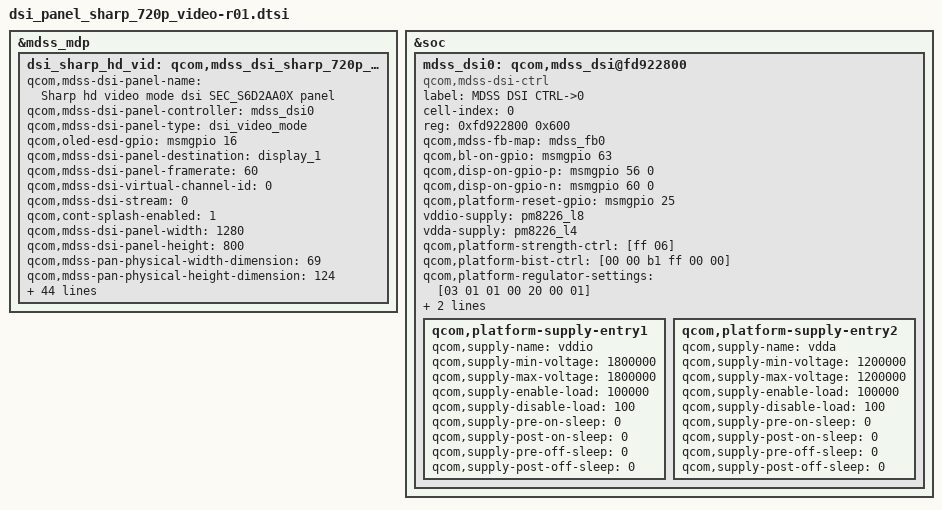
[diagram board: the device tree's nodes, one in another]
/* Copyright (c) 2013, The Linux Foundation. All rights reserved.
 *
 * This program is free software; you can redistribute it and/or modify
 * it under the terms of the GNU General Public License version 2 and
 * only version 2 as published by the Free Software Foundation.
 *
 * This program is distributed in the hope that it will be useful,
 * but WITHOUT ANY WARRANTY; without even the implied warranty of
 * MERCHANTABILITY or FITNESS FOR A PARTICULAR PURPOSE.  See the
 * GNU General Public License for more details.
 */
&mdss_mdp {
		dsi_sharp_hd_vid: qcom,mdss_dsi_sharp_720p_video {
		qcom,mdss-dsi-panel-name = "Sharp hd video mode dsi SEC_S6D2AA0X panel";
		qcom,mdss-dsi-panel-controller = <&mdss_dsi0>;
		qcom,mdss-dsi-panel-type = "dsi_video_mode";
		qcom,oled-esd-gpio = <&msmgpio 16 0>;
		qcom,mdss-dsi-panel-destination = "display_1";
		qcom,mdss-dsi-panel-framerate = <60>;
		qcom,mdss-dsi-virtual-channel-id = <0>;
		qcom,mdss-dsi-stream = <0>;
		qcom,cont-splash-enabled = <1>;
		qcom,mdss-dsi-panel-width = <1280>;
		qcom,mdss-dsi-panel-height = <800>;
		qcom,mdss-pan-physical-width-dimension = <69>; /* <Width> real size of panel in mm */
		qcom,mdss-pan-physical-height-dimension = <124>; /*<Height> real size of panel in mm */
		qcom,mdss-dsi-h-front-porch = <192>;
		qcom,mdss-dsi-h-back-porch = <30>;
		qcom,mdss-dsi-h-front-porch-jdi = <134>;	// Adding for JDI
		qcom,mdss-dsi-h-back-porch-jdi = <65>;		// Adding for JDI
		qcom,mdss-dsi-h-pulse-width = <4>;
		qcom,mdss-dsi-h-sync-skew = <0>;
		qcom,mdss-dsi-v-back-porch = <6>;
		qcom,mdss-dsi-v-front-porch = <8>;
		qcom,mdss-dsi-v-pulse-width = <2>;
		qcom,mdss-dsi-h-left-border = <0>;
		qcom,mdss-dsi-h-right-border = <0>;
		qcom,mdss-dsi-v-top-border = <0>;
		qcom,mdss-dsi-v-bottom-border = <0>;
		qcom,mdss-dsi-bpp = <24>;
		qcom,mdss-dsi-color-order = <0>;
		qcom,mdss-dsi-underflow-color = <0xff>;
		qcom,mdss-dsi-border-color = <0>;
		qcom,mdss-dsi-mdp-trigger = <0x0>;
		qcom,mdss-dsi-dma-trigger = <0x04>;
		qcom,mdss-dsi-bl-min-level = <10>;
		qcom,mdss-dsi-bl-max-level = <120>;
		qcom,mdss-dsi-bl-pmic-control-type = "bl_ctrl_dcs";
		qcom,mdss-pan-dsi-t-clk-pre = <0x1b>;
		qcom,mdss-pan-dsi-t-clk-post = <0x04>;
        qcom,mdss-dsi-panel-timings = [30 1C 12 00 42 44 18 20 16 03 04 00];
		qcom,mdss-dsi-lane-0-state;
		qcom,mdss-dsi-lane-1-state;
		qcom,mdss-dsi-lane-2-state;
		qcom,mdss-dsi-lane-3-state;
		qcom,mdss-dsi-bllp-eof-power-mode;
		qcom,mdss-dsi-bllp-power-mode;
		qcom,mdss-dsi-traffic-mode = <2>;
		qcom,mdss-force-clk-lane-hs = <1>;
		qcom,mdss-dsi-lane-map = <0>;
		qcom,mdss-dsi-h-sync-pulse = <0>;
		qcom,mdss-dsi-panel-clock-rate = <462000000>;


		qcom,mdss-dsi-on-command = [
/*TC358764/65XBG DSI Basic Parameters*/
			29 01 00 00 00 00 06 3C 01 06 00 05 00
			29 01 00 00 00 00 06 14 01 04 00 00 00
			29 01 00 00 00 00 06 64 01 04 00 00 00
			29 01 00 00 00 00 06 68 01 04 00 00 00
			29 01 00 00 00 00 06 6C 01 04 00 00 00
			29 01 00 00 00 00 06 70 01 04 00 00 00
			29 01 00 00 00 00 06 34 01 1F 00 00 00
			29 01 00 00 00 00 06 10 02 1F 00 00 00
			29 01 00 00 00 00 06 04 01 01 00 00 00
			29 01 00 00 00 00 06 04 02 01 00 00 00

/*TC358764/65XBG Timing and mode setting*/
			29 01 00 00 00 00 06 50 04 20 01 F0 03
			29 01 00 00 00 00 06 54 04 02 00 30 00
			29 01 00 00 00 00 06 58 04 20 03 30 00
			29 01 00 00 00 00 06 5C 04 02 00 40 00
			29 01 00 00 00 00 06 60 04 00 05 20 00

			29 01 00 00 00 00 06 64 04 01 00 00 00
			29 01 00 00 02 00 06 A0 04 06 80 44 00
			29 01 00 00 02 00 06 A0 04 06 80 04 00
			29 01 00 00 02 00 06 04 05 04 00 00 00
/*TC358764/65XBG LVDS Color mapping setting	*/

			29 01 00 00 00 00 06 80 04 00 01 02 03
			29 01 00 00 00 00 06 84 04 04 07 05 08
			29 01 00 00 00 00 06 88 04 09 0A 0E 0F
			29 01 00 00 00 00 06 8C 04 0B 0C 0D 10
			29 01 00 00 00 00 06 90 04 16 17 11 12
			29 01 00 00 00 00 06 94 04 13 14 15 1B
			29 01 00 00 00 00 06 98 04 18 19 1A 06
/*TC358764/65XBG LVDS enable*/
			29 01 00 00 00 00 06 9C 04 01 00 00 00
			];
		qcom,mdss-dsi-on-command-state = "dsi_lp_mode";
		qcom,mdss-dsi-off-command-state = "dsi_hs_mode";
		qcom,mdss-dsi-off-command = [29 01 00 00 01 00 06 A0 04 01 00 00 00
			29 01 00 00 00 00 06 9C 04 00 00 00 00];
	};
};
&soc {
	mdss_dsi0: qcom,mdss_dsi@fd922800 {
		compatible = "qcom,mdss-dsi-ctrl";
		label = "MDSS DSI CTRL->0";
		cell-index = <0>;
		reg = <0xfd922800 0x600>;
		qcom,mdss-fb-map = <&mdss_fb0>;
		qcom,bl-on-gpio = <&msmgpio 63 0>;
		qcom,disp-on-gpio-p = <&msmgpio 56 0>;
		qcom,disp-on-gpio-n = <&msmgpio 60 0>;
		qcom,platform-reset-gpio = <&msmgpio 25 0>;
		vddio-supply = <&pm8226_l8>;
		vdda-supply = <&pm8226_l4>;
		qcom,platform-strength-ctrl = [ff 06];
		qcom,platform-bist-ctrl = [00 00 b1 ff 00 00];
		qcom,platform-regulator-settings = [03 01 01 00 20 00 01];
		qcom,platform-lane-config = [00 00 00 00 00 00 00 01 75
			00 00 00 00 05 00 00 01 75
			00 00 00 00 0a 00 00 01 75
			00 00 00 00 0f 00 00 01 75
			00 c0 00 00 00 00 00 01 97];
		qcom,platform-supply-entry1 {
			qcom,supply-name = "vddio";
			qcom,supply-min-voltage = <1800000>;
			qcom,supply-max-voltage = <1800000>;
			qcom,supply-enable-load = <100000>;
			qcom,supply-disable-load = <100>;
			qcom,supply-pre-on-sleep = <0>;
			qcom,supply-post-on-sleep = <0>;
			qcom,supply-pre-off-sleep = <0>;
			qcom,supply-post-off-sleep = <0>;
		};
		qcom,platform-supply-entry2 {
			qcom,supply-name = "vdda";
			qcom,supply-min-voltage = <1200000>;
			qcom,supply-max-voltage = <1200000>;
			qcom,supply-enable-load = <100000>;
			qcom,supply-disable-load = <100>;
			qcom,supply-pre-on-sleep = <0>;
			qcom,supply-post-on-sleep = <0>;
			qcom,supply-pre-off-sleep = <0>;
			qcom,supply-post-off-sleep = <0>;
		};
	};
};
